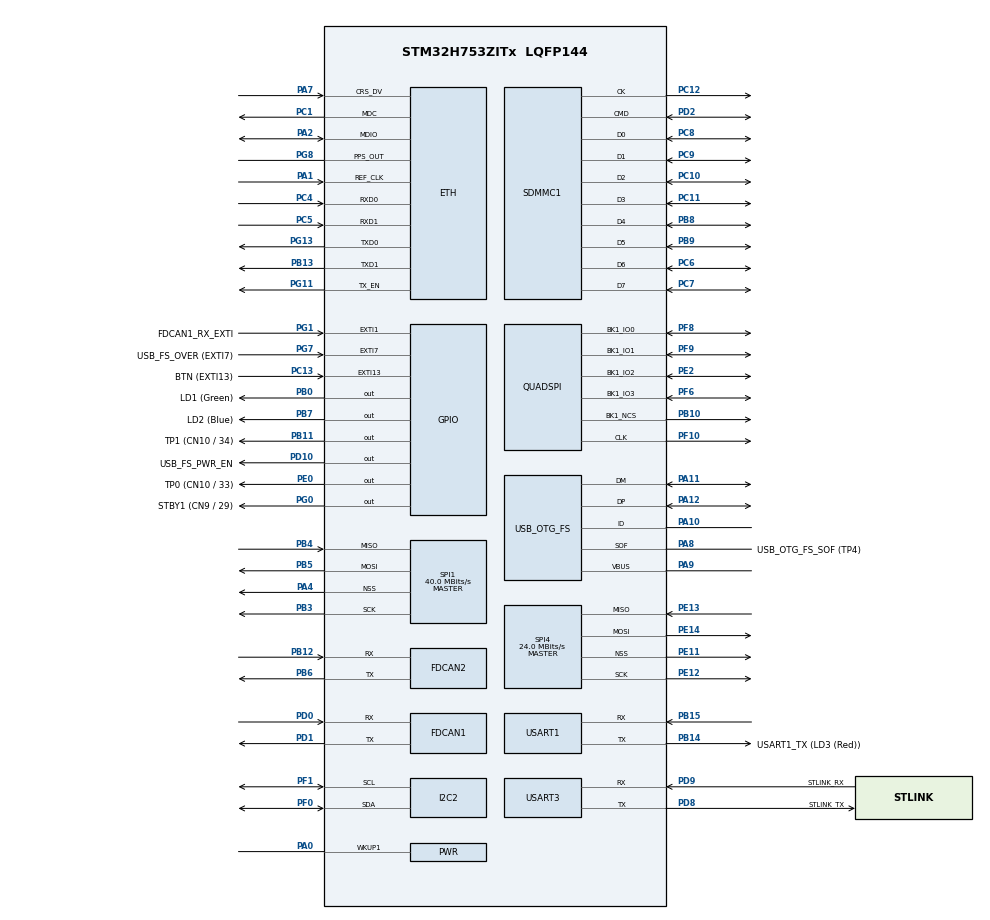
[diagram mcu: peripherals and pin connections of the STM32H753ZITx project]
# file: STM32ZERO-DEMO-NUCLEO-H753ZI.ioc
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CORTEX_M7.AccessPermission_S-Cortex_Memory_Protection_Unit_Region1_Settings_S=MPU_REGION_FULL_ACCESS
CORTEX_M7.AccessPermission_S-Cortex_Memory_Protection_Unit_Region2_Settings_S=MPU_REGION_FULL_ACCESS
CORTEX_M7.AccessPermission_S-Cortex_Memory_Protection_Unit_Region3_Settings_S=MPU_REGION_FULL_ACCESS
CORTEX_M7.BaseAddress_S-Cortex_Memory_Protection_Unit_Region1_Settings_S=0x30020000 /* SRAM2 */
CORTEX_M7.BaseAddress_S-Cortex_Memory_Protection_Unit_Region2_Settings_S=0x30040000 /* SRAM3 */
CORTEX_M7.BaseAddress_S-Cortex_Memory_Protection_Unit_Region3_Settings_S=0x30000000 /* SRAM1 */
CORTEX_M7.CPU_DCache=Enabled
CORTEX_M7.CPU_ICache=Enabled
CORTEX_M7.DisableExec_S-Cortex_Memory_Protection_Unit_Region1_Settings_S=MPU_INSTRUCTION_ACCESS_DISABLE
CORTEX_M7.DisableExec_S-Cortex_Memory_Protection_Unit_Region2_Settings_S=MPU_INSTRUCTION_ACCESS_DISABLE
CORTEX_M7.DisableExec_S-Cortex_Memory_Protection_Unit_Region3_Settings_S=MPU_INSTRUCTION_ACCESS_DISABLE
CORTEX_M7.Enable_S-Cortex_Memory_Protection_Unit_Region1_Settings_S=MPU_REGION_ENABLE
CORTEX_M7.Enable_S-Cortex_Memory_Protection_Unit_Region2_Settings_S=MPU_REGION_ENABLE
CORTEX_M7.Enable_S-Cortex_Memory_Protection_Unit_Region3_Settings_S=MPU_REGION_ENABLE
CORTEX_M7.IsBufferable_S-Cortex_Memory_Protection_Unit_Region2_Settings_S=MPU_ACCESS_BUFFERABLE
CORTEX_M7.IsBufferable_S-Cortex_Memory_Protection_Unit_Region3_Settings_S=MPU_ACCESS_BUFFERABLE
CORTEX_M7.IsCacheable_S-Cortex_Memory_Protection_Unit_Region2_Settings_S=MPU_ACCESS_NOT_CACHEABLE
CORTEX_M7.IsShareable_S-Cortex_Memory_Protection_Unit_Region2_Settings_S=MPU_ACCESS_SHAREABLE
CORTEX_M7.IsShareable_S-Cortex_Memory_Protection_Unit_Region3_Settings_S=MPU_ACCESS_SHAREABLE
CORTEX_M7.MPU_Control=MPU_PRIVILEGED_DEFAULT
CORTEX_M7.Size_S-Cortex_Memory_Protection_Unit_Region1_Settings_S=MPU_REGION_SIZE_128KB
CORTEX_M7.Size_S-Cortex_Memory_Protection_Unit_Region2_Settings_S=MPU_REGION_SIZE_512B
CORTEX_M7.Size_S-Cortex_Memory_Protection_Unit_Region3_Settings_S=MPU_REGION_SIZE_128KB
CORTEX_M7.TypeExtField_S-Cortex_Memory_Protection_Unit_Region1_Settings_S=MPU_TEX_LEVEL1
CORTEX_M7.default_mode_Activation=1
Dma.Request0=USART3_TX
Dma.Request1=USART3_RX
Dma.USART3_RX.1.Direction=DMA_PERIPH_TO_MEMORY
Dma.USART3_RX.1.EventEnable=DISABLE
Dma.USART3_RX.1.FIFOMode=DMA_FIFOMODE_DISABLE
Dma.USART3_RX.1.Instance=DMA2_Stream6
Dma.USART3_RX.1.MemDataAlignment=DMA_MDATAALIGN_BYTE
Dma.USART3_RX.1.MemInc=DMA_MINC_ENABLE
Dma.USART3_RX.1.Mode=DMA_NORMAL
Dma.USART3_RX.1.PeriphDataAlignment=DMA_PDATAALIGN_BYTE
Dma.USART3_RX.1.PeriphInc=DMA_PINC_DISABLE
Dma.USART3_RX.1.Polarity=HAL_DMAMUX_REQ_GEN_RISING
Dma.USART3_RX.1.Priority=DMA_PRIORITY_LOW
Dma.USART3_RX.1.RequestNumber=1
Dma.USART3_RX.1.SignalID=NONE
Dma.USART3_RX.1.SyncEnable=DISABLE
Dma.USART3_RX.1.SyncPolarity=HAL_DMAMUX_SYNC_NO_EVENT
Dma.USART3_RX.1.SyncRequestNumber=1
Dma.USART3_RX.1.SyncSignalID=NONE
Dma.USART3_TX.0.Direction=DMA_MEMORY_TO_PERIPH
Dma.USART3_TX.0.EventEnable=DISABLE
Dma.USART3_TX.0.FIFOMode=DMA_FIFOMODE_DISABLE
Dma.USART3_TX.0.Instance=DMA2_Stream7
Dma.USART3_TX.0.MemDataAlignment=DMA_MDATAALIGN_BYTE
Dma.USART3_TX.0.MemInc=DMA_MINC_ENABLE
Dma.USART3_TX.0.Mode=DMA_NORMAL
Dma.USART3_TX.0.PeriphDataAlignment=DMA_PDATAALIGN_BYTE
Dma.USART3_TX.0.PeriphInc=DMA_PINC_DISABLE
Dma.USART3_TX.0.Polarity=HAL_DMAMUX_REQ_GEN_RISING
Dma.USART3_TX.0.Priority=DMA_PRIORITY_LOW
Dma.USART3_TX.0.RequestNumber=1
Dma.USART3_TX.0.SignalID=NONE
Dma.USART3_TX.0.SyncEnable=DISABLE
Dma.USART3_TX.0.SyncPolarity=HAL_DMAMUX_SYNC_NO_EVENT
Dma.USART3_TX.0.SyncRequestNumber=1
Dma.USART3_TX.0.SyncSignalID=NONE
ETH.MediaInterface=HAL_ETH_RMII_MODE
FDCAN1.AutoRetransmission=ENABLE
FDCAN1.CalculateBaudRateNominal=2000000
FDCAN1.CalculateTimeBitNominal=500
FDCAN1.CalculateTimeQuantumNominal=25.0
FDCAN1.DataPrescaler=2
FDCAN1.DataTimeSeg1=14
FDCAN1.DataTimeSeg2=5
FDCAN1.FrameFormat=FDCAN_FRAME_FD_BRS
FDCAN1.NominalPrescaler=2
FDCAN1.NominalTimeSeg1=14
FDCAN1.NominalTimeSeg2=5
FDCAN1.RxBufferSize=FDCAN_DATA_BYTES_64
FDCAN1.RxBuffersNbr=1
FDCAN1.RxFifo0ElmtSize=FDCAN_DATA_BYTES_64
FDCAN1.RxFifo0ElmtsNbr=1
FDCAN1.RxFifo1ElmtSize=FDCAN_DATA_BYTES_64
FDCAN1.RxFifo1ElmtsNbr=1
FDCAN1.StdFiltersNbr=1
FDCAN1.TxBuffersNbr=31
FDCAN1.TxElmtSize=FDCAN_DATA_BYTES_64
FDCAN1.TxFifoQueueElmtsNbr=1
FDCAN2.AutoRetransmission=ENABLE
FDCAN2.CalculateBaudRateNominal=1666666
FDCAN2.CalculateTimeBitNominal=600
FDCAN2.CalculateTimeQuantumNominal=200.0
FDCAN2.DataPrescaler=2
FDCAN2.MessageRAMOffset=1280
FDCAN2.RxBuffersNbr=1
FDCAN2.RxFifo0ElmtsNbr=1
FDCAN2.RxFifo1ElmtsNbr=1
FDCAN2.TxBuffersNbr=1
FDCAN2.TxFifoQueueElmtsNbr=0
FREERTOS.Tasks01=defaultTask,24,128,StartDefaultTask,Default,NULL,Dynamic,NULL,NULL
FREERTOS.configTOTAL_HEAP_SIZE=65536
FREERTOS.configUSE_NEWLIB_REENTRANT=1
I2C2.Timing=0x20303E5D
LWIP.BSP.number=1
LWIP.GATEWAY_ADDRESS=192.168.010.001
LWIP.IP_ADDRESS=192.168.010.003
LWIP.LWIP_DHCP=0
LWIP.LWIP_RAM_HEAP_POINTER=0x30020000 /* SRAM2 */
LWIP.LWIP_TCPIP_CORE_LOCKING=1
LWIP.LWIP_TCPIP_CORE_LOCKING_INPUT=1
LWIP.MEM_SIZE=131040
LWIP.NETMASK_ADDRESS=255.255.255.000
LWIP.Version=v2.1.2_Cube
LWIP0.BSP.STBoard=false
LWIP0.BSP.api=BSP_COMPONENT_DRIVER
LWIP0.BSP.component=LAN8742
LWIP0.BSP.instance=LAN8742
LWIP0.BSP.name=Driver_PHY
LWIP0.BSP.semaphore=S_LAN8742
LWIP0.BSP.solution=LAN8742
Mcu.Family=STM32H7
Mcu.Name=STM32H753ZITx
Mcu.Package=LQFP144
NVIC.DMA2_Stream6_IRQn=true\:5\:0\:false\:false\:true\:true\:false\:true\:true
NVIC.DMA2_Stream7_IRQn=true\:5\:0\:false\:false\:true\:true\:false\:true\:true
NVIC.EXTI15_10_IRQn=true\:5\:0\:false\:false\:true\:true\:false\:true\:true
NVIC.FDCAN1_IT0_IRQn=true\:5\:0\:false\:false\:true\:true\:true\:true\:true
NVIC.FDCAN1_IT1_IRQn=true\:5\:0\:false\:false\:true\:true\:true\:true\:true
NVIC.FDCAN_CAL_IRQn=true\:5\:0\:false\:false\:true\:true\:true\:true\:true
NVIC.PriorityGroup=NVIC_PRIORITYGROUP_4
NVIC.TIM17_IRQn=true\:15\:0\:false\:false\:true\:false\:false\:true\:true
NVIC.TimeBase=TIM17_IRQn
NVIC.TimeBaseIP=TIM17
NVIC.USART3_IRQn=true\:5\:0\:false\:false\:true\:true\:true\:true\:true
PA0.Mode=WakeUp1
PA0.Signal=PWR_WKUP1
PA1.GPIO_Speed_Default_HIGH=GPIO_SPEED_FREQ_HIGH
PA1.Mode=RMII_PTP_Synchro
PA1.Signal=ETH_REF_CLK
PA10.GPIO_Speed=GPIO_SPEED_FREQ_LOW
PA10.Mode=OTG/Dual_Role_Device
PA10.Signal=USB_OTG_FS_ID
PA11.GPIO_Speed=GPIO_SPEED_FREQ_HIGH
PA11.Mode=OTG/Dual_Role_Device
PA11.Signal=USB_OTG_FS_DM
PA12.GPIO_Speed=GPIO_SPEED_FREQ_HIGH
PA12.Mode=OTG/Dual_Role_Device
PA12.Signal=USB_OTG_FS_DP
PA13\ (JTMS/SWDIO).Mode=Serial_Wire
PA13\ (JTMS/SWDIO).Signal=DEBUG_JTMS-SWDIO
PA14\ (JTCK/SWCLK).Mode=Serial_Wire
PA14\ (JTCK/SWCLK).Signal=DEBUG_JTCK-SWCLK
PA2.GPIO_Speed_Default_HIGH=GPIO_SPEED_FREQ_HIGH
PA2.Mode=RMII_PTP_Synchro
PA2.Signal=ETH_MDIO
PA4.GPIO_Speed=GPIO_SPEED_FREQ_MEDIUM
PA4.Mode=NSS_Signal_Hard_Output
PA4.Signal=SPI1_NSS
PA7.GPIO_Speed_Default_HIGH=GPIO_SPEED_FREQ_HIGH
PA7.Mode=RMII_PTP_Synchro
PA7.Signal=ETH_CRS_DV
PA8.GPIO_Label=USB_OTG_FS_SOF (TP4)
PA8.GPIO_Speed=GPIO_SPEED_FREQ_LOW
PA8.Mode=Activate_SOF_FS
PA8.Signal=USB_OTG_FS_SOF
PA9.Mode=Activate_VBUS
PA9.Signal=USB_OTG_FS_VBUS
PB0.GPIO_Label=LD1 (Green)
PB0.Signal=GPIO_Output
PB10.GPIO_Speed=GPIO_SPEED_FREQ_HIGH
PB10.Mode=Single Bank 1
PB10.Signal=QUADSPI_BK1_NCS
PB11.GPIO_Label=TP1 (CN10 / 34)
PB11.Signal=GPIO_Output
PB12.Mode=FDCAN_Activate
PB12.Signal=FDCAN2_RX
PB13.GPIO_Speed_Default_HIGH=GPIO_SPEED_FREQ_HIGH
PB13.Mode=RMII_PTP_Synchro
PB13.Signal=ETH_TXD1
PB14.GPIO_Label=USART1_TX (LD3 (Red))
PB14.Signal=SharedStack_PB14
PB14.Stacked=true
PB15.Mode=Asynchronous
PB15.Signal=USART1_RX
PB3\ (JTDO/TRACESWO).GPIO_Speed=GPIO_SPEED_FREQ_VERY_HIGH
PB3\ (JTDO/TRACESWO).Mode=Full_Duplex_Master
PB3\ (JTDO/TRACESWO).Signal=SPI1_SCK
PB4\ (NJTRST).GPIO_Speed=GPIO_SPEED_FREQ_HIGH
PB4\ (NJTRST).Mode=Full_Duplex_Master
PB4\ (NJTRST).Signal=SPI1_MISO
PB5.GPIO_Speed=GPIO_SPEED_FREQ_HIGH
PB5.Mode=Full_Duplex_Master
PB5.Signal=SPI1_MOSI
PB6.Mode=FDCAN_Activate
PB6.Signal=FDCAN2_TX
PB7.GPIO_Label=LD2 (Blue)
PB7.Signal=GPIO_Output
PB8.Mode=mmc_8_bits_Wide_bus
PB8.Signal=SDMMC1_D4
PB9.Mode=mmc_8_bits_Wide_bus
PB9.Signal=SDMMC1_D5
PC1.GPIO_Speed_Default_HIGH=GPIO_SPEED_FREQ_HIGH
PC1.Mode=RMII_PTP_Synchro
PC1.Signal=ETH_MDC
PC10.GPIO_Speed_High_Default=GPIO_SPEED_FREQ_HIGH
PC10.Mode=mmc_8_bits_Wide_bus
PC10.Signal=SDMMC1_D2
PC11.GPIO_Speed_High_Default=GPIO_SPEED_FREQ_HIGH
PC11.Mode=mmc_8_bits_Wide_bus
PC11.Signal=SDMMC1_D3
PC12.Mode=mmc_8_bits_Wide_bus
PC12.Signal=SDMMC1_CK
PC13.GPIO_Label=BTN (EXTI13)
PC13.Signal=GPXTI13
PC14-OSC32_IN\ (OSC32_IN).Mode=LSE-External-Oscillator
PC14-OSC32_IN\ (OSC32_IN).Signal=RCC_OSC32_IN
PC15-OSC32_OUT\ (OSC32_OUT).Mode=LSE-External-Oscillator
PC15-OSC32_OUT\ (OSC32_OUT).Signal=RCC_OSC32_OUT
PC4.GPIO_Speed_Default_HIGH=GPIO_SPEED_FREQ_HIGH
PC4.Mode=RMII_PTP_Synchro
PC4.Signal=ETH_RXD0
PC5.GPIO_Speed_Default_HIGH=GPIO_SPEED_FREQ_HIGH
PC5.Mode=RMII_PTP_Synchro
PC5.Signal=ETH_RXD1
PC6.Mode=mmc_8_bits_Wide_bus
PC6.Signal=SDMMC1_D6
PC7.Mode=mmc_8_bits_Wide_bus
PC7.Signal=SDMMC1_D7
PC8.GPIO_Speed_High_Default=GPIO_SPEED_FREQ_HIGH
PC8.Mode=mmc_8_bits_Wide_bus
PC8.Signal=SDMMC1_D0
PC9.GPIO_Speed_High_Default=GPIO_SPEED_FREQ_HIGH
PC9.Mode=mmc_8_bits_Wide_bus
PC9.Signal=SDMMC1_D1
PD0.GPIO_Speed=GPIO_SPEED_FREQ_VERY_HIGH
PD0.Mode=FDCAN_Activate
PD0.Signal=FDCAN1_RX
PD1.GPIO_Speed=GPIO_SPEED_FREQ_VERY_HIGH
PD1.Mode=FDCAN_Activate
PD1.Signal=FDCAN1_TX
PD10.GPIO_Label=USB_FS_PWR_EN
PD10.Signal=GPIO_Output
PD2.GPIO_Speed_High_Default=GPIO_SPEED_FREQ_HIGH
PD2.Mode=mmc_8_bits_Wide_bus
PD2.Signal=SDMMC1_CMD
PD8.GPIO_Label=STLINK_TX
PD8.Mode=Asynchronous
PD8.Signal=USART3_TX
PD9.GPIO_Label=STLINK_RX
PD9.Mode=Asynchronous
PD9.Signal=USART3_RX
PE0.GPIO_Label=TP0 (CN10 / 33)
PE0.Signal=GPIO_Output
PE11.Mode=NSS_Signal_Hard_Output
PE11.Signal=SPI4_NSS
PE12.Mode=Full_Duplex_Master
PE12.Signal=SPI4_SCK
PE13.Mode=Full_Duplex_Master
PE13.Signal=SPI4_MISO
PE14.Mode=Full_Duplex_Master
PE14.Signal=SPI4_MOSI
PE2.GPIO_Speed=GPIO_SPEED_FREQ_HIGH
PE2.Mode=Single Bank 1
PE2.Signal=QUADSPI_BK1_IO2
PF0.Mode=I2C
PF0.Signal=I2C2_SDA
PF1.Mode=I2C
PF1.Signal=I2C2_SCL
PF10.GPIO_Speed=GPIO_SPEED_FREQ_HIGH
PF10.Mode=Single Bank 1
PF10.Signal=QUADSPI_CLK
PF6.GPIO_Speed=GPIO_SPEED_FREQ_HIGH
PF6.Mode=Single Bank 1
PF6.Signal=QUADSPI_BK1_IO3
PF8.GPIO_Speed=GPIO_SPEED_FREQ_HIGH
PF8.Mode=Single Bank 1
PF8.Signal=QUADSPI_BK1_IO0
PF9.GPIO_Speed=GPIO_SPEED_FREQ_HIGH
PF9.Mode=Single Bank 1
PF9.Signal=QUADSPI_BK1_IO1
PG0.GPIO_Label=STBY1 (CN9 / 29)
PG0.Signal=GPIO_Output
PG1.GPIO_Label=FDCAN1_RX_EXTI
PG1.Signal=GPXTI1
PG11.GPIO_Speed_Default_HIGH=GPIO_SPEED_FREQ_HIGH
PG11.Mode=RMII_PTP_Synchro
PG11.Signal=ETH_TX_EN
PG13.GPIO_Speed_Default_HIGH=GPIO_SPEED_FREQ_HIGH
PG13.Mode=RMII_PTP_Synchro
PG13.Signal=ETH_TXD0
PG7.GPIO_Label=USB_FS_OVER (EXTI7)
PG7.Signal=GPXTI7
PG8.GPIO_Speed=GPIO_SPEED_FREQ_LOW
PG8.GPIO_Speed_Default_HIGH=GPIO_SPEED_FREQ_HIGH
PG8.Mode=RMII_PTP_Synchro
PG8.Signal=ETH_PPS_OUT
PH0-OSC_IN\ (PH0).Mode=HSE-External-Clock-Source
PH0-OSC_IN\ (PH0).Signal=RCC_OSC_IN
PH1-OSC_OUT\ (PH1).Signal=RCC_OSC_OUT
ProjectManager.HeapSize=0x200
ProjectManager.StackSize=0x400
ProjectManager.TargetToolchain=STM32CubeIDE
RCC.ADCCLockSelection=RCC_ADCCLKSOURCE_PLL3
RCC.ADCFreq_Value=48000000
RCC.APB1Freq_Value=120000000
RCC.APB2Freq_Value=120000000
RCC.APB3Freq_Value=120000000
RCC.APB4Freq_Value=120000000
RCC.CortexFreq_Value=480000000
RCC.D1PPRE=RCC_APB3_DIV2
RCC.D2PPRE1=RCC_APB1_DIV2
RCC.D2PPRE2=RCC_APB2_DIV2
RCC.D3PPRE=RCC_APB4_DIV2
RCC.DIVM1=4
RCC.DIVM2=4
RCC.DIVM3=4
RCC.DIVN1=480
RCC.DIVN2=480
RCC.DIVN3=480
RCC.DIVP2=12
RCC.DIVP3=10
RCC.DIVQ1=12
RCC.DIVQ2=12
RCC.DIVQ3=20
RCC.DIVR1=10
RCC.DIVR2=10
RCC.DIVR3=20
RCC.HCLKFreq_Value=240000000
RCC.HPRE=RCC_HCLK_DIV2
RCC.HSE_VALUE=8000000
RCC.I2C123CLockSelection=RCC_I2C123CLKSOURCE_PLL3
RCC.LPTIM1CLockSelection=RCC_LPTIM1CLKSOURCE_PLL2
RCC.PLLFRACN=0
RCC.PLLSourceVirtual=RCC_PLLSOURCE_HSE
RCC.PWR_Regulator_Voltage_Scale=PWR_REGULATOR_VOLTAGE_SCALE0
RCC.QSPICLockSelection=RCC_QSPICLKSOURCE_PLL
RCC.SYSCLKFreq_VALUE=480000000
RCC.SYSCLKSource=RCC_SYSCLKSOURCE_PLLCLK
RCC.Spi45ClockSelection=RCC_SPI45CLKSOURCE_PLL3
RCC.USART16CLockSelection=RCC_USART16CLKSOURCE_PLL3
RCC.USART234578CLockSelection=RCC_USART234578CLKSOURCE_PLL3
RCC.USBCLockSelection=RCC_USBCLKSOURCE_PLL3
RCC.USBFreq_Value=48000000
SDMMC1.ClockDiv=1
SH.SharedStack_PB14.0=GPIO_Output+0
SH.SharedStack_PB14.1=USART1_TX,Asynchronous
SPI1.CalculateBaudRate=40.0 MBits/s
SPI1.DataSize=SPI_DATASIZE_8BIT
SPI1.Direction=SPI_DIRECTION_2LINES
SPI1.Mode=SPI_MODE_MASTER
SPI1.VirtualNSS=VM_NSSHARD
SPI1.VirtualType=VM_MASTER
SPI4.CalculateBaudRate=24.0 MBits/s
SPI4.Direction=SPI_DIRECTION_2LINES
SPI4.Mode=SPI_MODE_MASTER
SPI4.VirtualNSS=VM_NSSHARD
SPI4.VirtualType=VM_MASTER
TIM12.TIM_MasterOutputTrigger=TIM_TRGO_UPDATE
TIM2.Prescaler=0 /* for ETH PPS */
TIM3.Prescaler=(240-1) /* 240Mhz / 240 \= 1Mhz \= 1us */
TIM3.TIM_MasterOutputTrigger=TIM_TRGO_UPDATE
TIM4.TIM_MasterOutputTrigger=TIM_TRGO_UPDATE
TIM5.Prescaler=(240-1) /* 240Mhz / 240 \= 1Mhz \= 1us */ /* fdcan1_soc, USBx_SOF */
TIM5.TIM_MasterOutputTrigger=TIM_TRGO_UPDATE
USART1.VirtualMode-Asynchronous=VM_ASYNC
USART3.VirtualMode-Asynchronous=VM_ASYNC
VP_FREERTOS_VS_CMSIS_V2.Mode=CMSIS_V2
VP_LWIP_VS_Enabled.Mode=Enabled
VP_MEMORYMAP_VS_MEMORYMAP.Mode=CurAppReg
VP_SYS_VS_tim17.Mode=TIM17
VP_TIM12_VS_ClockSourceITR.Mode=TriggerSource_ITR0
VP_TIM12_VS_ControllerModeClock.Mode=Clock Mode
VP_TIM2_VS_ClockSourceITR.Mode=TriggerSource_ITR4
VP_TIM2_VS_ControllerModeClock.Mode=Clock Mode
VP_TIM3_VS_ClockSourceINT.Mode=Internal
VP_TIM4_VS_ClockSourceITR.Mode=TriggerSource_ITR2
VP_TIM4_VS_ControllerModeClock.Mode=Clock Mode
VP_TIM5_VS_ClockSourceINT.Mode=Internal
VP_TIM8_VS_ClockSourceITR.Mode=TriggerSource_ITR3
VP_TIM8_VS_ControllerModeClock.Mode=Clock Mode
board=NUCLEO-H753ZI

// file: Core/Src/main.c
/* USER CODE BEGIN Header */
/**
  ******************************************************************************
  * @file           : main.c
  * @brief          : Main program body
  ******************************************************************************
  * @attention
  *
  * Copyright (c) 2026 STMicroelectronics.
  * All rights reserved.
  *
  * This software is licensed under terms that can be found in the LICENSE file
  * in the root directory of this software component.
  * If no LICENSE file comes with this software, it is provided AS-IS.
  *
  ******************************************************************************
  */
/* USER CODE END Header */
#include "main.h"
#include "cmsis_os.h"
#include "dma.h"
#include "fdcan.h"
#include "i2c.h"
#include "lwip.h"
#include "quadspi.h"
#include "sdmmc.h"
#include "spi.h"
#include "tim.h"
#include "usart.h"
#include "usb_otg.h"
#include "gpio.h"

void SystemClock_Config(void);
void PeriphCommonClock_Config(void);
static void MPU_Config(void);
void MX_FREERTOS_Init(void);
/* USER CODE BEGIN PFP */
extern __NO_RETURN void app_init(void);
/* USER CODE END PFP */

int main(void)
{

  /* MPU Configuration--------------------------------------------------------*/
  MPU_Config();

  /* Enable the CPU Cache */

  /* Enable I-Cache---------------------------------------------------------*/
  SCB_EnableICache();

  /* Enable D-Cache---------------------------------------------------------*/
  SCB_EnableDCache();

  /* MCU Configuration--------------------------------------------------------*/

  /* Reset of all peripherals, Initializes the Flash interface and the Systick. */
  HAL_Init();

  /* Configure the system clock */
  SystemClock_Config();

  /* Configure the peripherals common clocks */
  PeriphCommonClock_Config();

  /* Initialize all configured peripherals */
  MX_GPIO_Init();
  MX_DMA_Init();
  MX_TIM12_Init();
  MX_TIM4_Init();
  MX_TIM3_Init();
  MX_TIM2_Init();
  MX_TIM5_Init();
  MX_USART3_UART_Init();
  MX_USART1_UART_Init();
  MX_QUADSPI_Init();
  MX_SDMMC1_MMC_Init();
  MX_I2C2_Init();
  MX_SPI1_Init();
  MX_SPI4_Init();
  MX_FDCAN1_Init();
  MX_USB_OTG_FS_USB_Init();
  MX_TIM8_Init();
  MX_FDCAN2_Init();
  /* USER CODE BEGIN 2 */
  app_init();
#if 0
  /* USER CODE END 2 */

  /* Init scheduler */
  osKernelInitialize();  /* Call init function for freertos objects (in cmsis_os2.c) */
  MX_FREERTOS_Init();

  /* Start scheduler */
  osKernelStart();

  /* We should never get here as control is now taken by the scheduler */

  /* Infinite loop */
  while (1)
  {

    /* USER CODE BEGIN 3 */
  }
#endif
  /* USER CODE END 3 */
}

void SystemClock_Config(void)
{
  RCC_OscInitTypeDef RCC_OscInitStruct = {0};
  RCC_ClkInitTypeDef RCC_ClkInitStruct = {0};

  /** Supply configuration update enable
  */
  HAL_PWREx_ConfigSupply(PWR_LDO_SUPPLY);

  /** Configure the main internal regulator output voltage
  */
  __HAL_PWR_VOLTAGESCALING_CONFIG(PWR_REGULATOR_VOLTAGE_SCALE0);

  while(!__HAL_PWR_GET_FLAG(PWR_FLAG_VOSRDY)) {}

  /** Initializes the RCC Oscillators according to the specified parameters
  * in the RCC_OscInitTypeDef structure.
  */
  RCC_OscInitStruct.OscillatorType = RCC_OSCILLATORTYPE_HSE;
  RCC_OscInitStruct.HSEState = RCC_HSE_BYPASS;
  RCC_OscInitStruct.PLL.PLLState = RCC_PLL_ON;
  RCC_OscInitStruct.PLL.PLLSource = RCC_PLLSOURCE_HSE;
  RCC_OscInitStruct.PLL.PLLM = 4;
  RCC_OscInitStruct.PLL.PLLN = 480;
  RCC_OscInitStruct.PLL.PLLP = 2;
  RCC_OscInitStruct.PLL.PLLQ = 12;
  RCC_OscInitStruct.PLL.PLLR = 10;
  RCC_OscInitStruct.PLL.PLLRGE = RCC_PLL1VCIRANGE_1;
  RCC_OscInitStruct.PLL.PLLVCOSEL = RCC_PLL1VCOWIDE;
  RCC_OscInitStruct.PLL.PLLFRACN = 0;
  if (HAL_RCC_OscConfig(&RCC_OscInitStruct) != HAL_OK)
  {
    Error_Handler();
  }

  /** Initializes the CPU, AHB and APB buses clocks
  */
  RCC_ClkInitStruct.ClockType = RCC_CLOCKTYPE_HCLK|RCC_CLOCKTYPE_SYSCLK
                              |RCC_CLOCKTYPE_PCLK1|RCC_CLOCKTYPE_PCLK2
                              |RCC_CLOCKTYPE_D3PCLK1|RCC_CLOCKTYPE_D1PCLK1;
  RCC_ClkInitStruct.SYSCLKSource = RCC_SYSCLKSOURCE_PLLCLK;
  RCC_ClkInitStruct.SYSCLKDivider = RCC_SYSCLK_DIV1;
  RCC_ClkInitStruct.AHBCLKDivider = RCC_HCLK_DIV2;
  RCC_ClkInitStruct.APB3CLKDivider = RCC_APB3_DIV2;
  RCC_ClkInitStruct.APB1CLKDivider = RCC_APB1_DIV2;
  RCC_ClkInitStruct.APB2CLKDivider = RCC_APB2_DIV2;
  RCC_ClkInitStruct.APB4CLKDivider = RCC_APB4_DIV2;

  if (HAL_RCC_ClockConfig(&RCC_ClkInitStruct, FLASH_LATENCY_4) != HAL_OK)
  {
    Error_Handler();
  }
}

void PeriphCommonClock_Config(void)
{
  RCC_PeriphCLKInitTypeDef PeriphClkInitStruct = {0};

  /** Initializes the peripherals clock
  */
  PeriphClkInitStruct.PeriphClockSelection = RCC_PERIPHCLK_USB|RCC_PERIPHCLK_I2C2
                              |RCC_PERIPHCLK_SPI4|RCC_PERIPHCLK_USART1
                              |RCC_PERIPHCLK_USART3;
  PeriphClkInitStruct.PLL3.PLL3M = 4;
  PeriphClkInitStruct.PLL3.PLL3N = 480;
  PeriphClkInitStruct.PLL3.PLL3P = 10;
  PeriphClkInitStruct.PLL3.PLL3Q = 20;
  PeriphClkInitStruct.PLL3.PLL3R = 20;
  PeriphClkInitStruct.PLL3.PLL3RGE = RCC_PLL3VCIRANGE_1;
  PeriphClkInitStruct.PLL3.PLL3VCOSEL = RCC_PLL3VCOWIDE;
  PeriphClkInitStruct.PLL3.PLL3FRACN = 0;
  PeriphClkInitStruct.Spi45ClockSelection = RCC_SPI45CLKSOURCE_PLL3;
  PeriphClkInitStruct.Usart234578ClockSelection = RCC_USART234578CLKSOURCE_PLL3;
  PeriphClkInitStruct.Usart16ClockSelection = RCC_USART16CLKSOURCE_PLL3;
  PeriphClkInitStruct.I2c123ClockSelection = RCC_I2C123CLKSOURCE_PLL3;
  PeriphClkInitStruct.UsbClockSelection = RCC_USBCLKSOURCE_PLL3;
  if (HAL_RCCEx_PeriphCLKConfig(&PeriphClkInitStruct) != HAL_OK)
  {
    Error_Handler();
  }
}

 /* MPU Configuration */

void MPU_Config(void)
{
  MPU_Region_InitTypeDef MPU_InitStruct = {0};

  /* Disables the MPU */
  HAL_MPU_Disable();

  /** Initializes and configures the Region and the memory to be protected
  */
  MPU_InitStruct.Enable = MPU_REGION_ENABLE;
  MPU_InitStruct.Number = MPU_REGION_NUMBER0;
  MPU_InitStruct.BaseAddress = 0x0;
  MPU_InitStruct.Size = MPU_REGION_SIZE_4GB;
  MPU_InitStruct.SubRegionDisable = 0x87;
  MPU_InitStruct.TypeExtField = MPU_TEX_LEVEL0;
  MPU_InitStruct.AccessPermission = MPU_REGION_NO_ACCESS;
  MPU_InitStruct.DisableExec = MPU_INSTRUCTION_ACCESS_DISABLE;
  MPU_InitStruct.IsShareable = MPU_ACCESS_SHAREABLE;
  MPU_InitStruct.IsCacheable = MPU_ACCESS_NOT_CACHEABLE;
  MPU_InitStruct.IsBufferable = MPU_ACCESS_NOT_BUFFERABLE;

  HAL_MPU_ConfigRegion(&MPU_InitStruct);

  /** Initializes and configures the Region and the memory to be protected
  */
  MPU_InitStruct.Number = MPU_REGION_NUMBER1;
  MPU_InitStruct.BaseAddress = 0x30020000 /* SRAM2 */;
  MPU_InitStruct.Size = MPU_REGION_SIZE_128KB;
  MPU_InitStruct.SubRegionDisable = 0x0;
  MPU_InitStruct.TypeExtField = MPU_TEX_LEVEL1;
  MPU_InitStruct.AccessPermission = MPU_REGION_FULL_ACCESS;
  MPU_InitStruct.IsShareable = MPU_ACCESS_NOT_SHAREABLE;

  HAL_MPU_ConfigRegion(&MPU_InitStruct);

  /** Initializes and configures the Region and the memory to be protected
  */
  MPU_InitStruct.Number = MPU_REGION_NUMBER2;
  MPU_InitStruct.BaseAddress = 0x30040000 /* SRAM3 */;
  MPU_InitStruct.Size = MPU_REGION_SIZE_512B;
  MPU_InitStruct.TypeExtField = MPU_TEX_LEVEL0;
  MPU_InitStruct.IsShareable = MPU_ACCESS_SHAREABLE;
  MPU_InitStruct.IsBufferable = MPU_ACCESS_BUFFERABLE;

  HAL_MPU_ConfigRegion(&MPU_InitStruct);

  /** Initializes and configures the Region and the memory to be protected
  */
  MPU_InitStruct.Number = MPU_REGION_NUMBER3;
  MPU_InitStruct.BaseAddress = 0x30000000 /* SRAM1 */;
  MPU_InitStruct.Size = MPU_REGION_SIZE_128KB;

  HAL_MPU_ConfigRegion(&MPU_InitStruct);
  /* Enables the MPU */
  HAL_MPU_Enable(MPU_PRIVILEGED_DEFAULT);

}

void HAL_TIM_PeriodElapsedCallback(TIM_HandleTypeDef *htim)
{
  if (htim->Instance == TIM17)
  {
    HAL_IncTick();
  }
}

void Error_Handler(void)
{
  __disable_irq();
  while (1)
  {
  }
}
